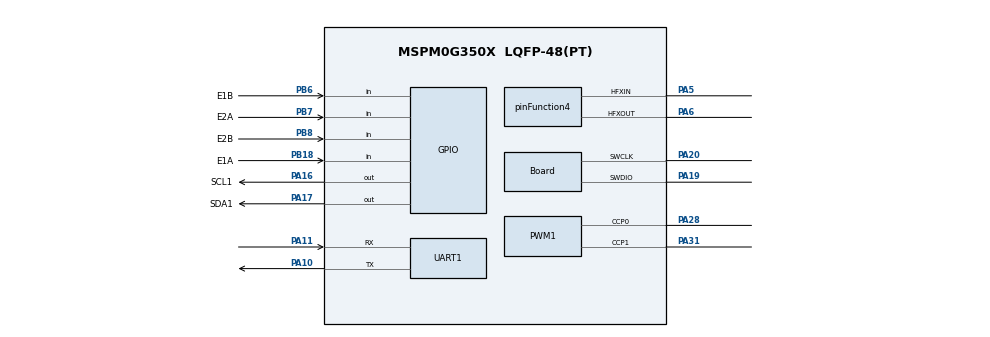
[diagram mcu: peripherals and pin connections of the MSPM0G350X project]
/**
 * @cliArgs --device "MSPM0G350X" --part "Default" --package "LQFP-48(PT)" --product "mspm0_sdk@2.03.00.07"
 * @versions {"tool":"1.22.0+3893"}
 */

/**
 * Import the modules used in this configuration.
 */
const GPIO          = scripting.addModule("/ti/driverlib/GPIO", {}, false);
const GPIO1         = GPIO.addInstance();
const GPIO2         = GPIO.addInstance();
const GPIO3         = GPIO.addInstance();
const GPIO4         = GPIO.addInstance();
const GPIO5         = GPIO.addInstance();
const GPIO6         = GPIO.addInstance();
const GPIO7         = GPIO.addInstance();
const PWM           = scripting.addModule("/ti/driverlib/PWM", {}, false);
const PWM1          = PWM.addInstance();
const SYSCTL        = scripting.addModule("/ti/driverlib/SYSCTL");
const SYSTICK       = scripting.addModule("/ti/driverlib/SYSTICK");
const TIMER         = scripting.addModule("/ti/driverlib/TIMER", {}, false);
const TIMER1        = TIMER.addInstance();
const UART          = scripting.addModule("/ti/driverlib/UART", {}, false);
const UART1         = UART.addInstance();
const ProjectConfig = scripting.addModule("/ti/project_config/ProjectConfig");

/**
 * Write custom configuration values to the imported modules.
 */
const divider6       = system.clockTree["PLL_CLK2X_DIV"];
divider6.divideValue = 4;

const divider7       = system.clockTree["PLL_PDIV"];
divider7.divideValue = 2;

const divider9       = system.clockTree["UDIV"];
divider9.divideValue = 2;

const gate7  = system.clockTree["MFCLKGATE"];
gate7.enable = true;

const gate8  = system.clockTree["MFPCLKGATE"];
gate8.enable = true;

const multiplier2         = system.clockTree["PLL_QDIV"];
multiplier2.multiplyValue = 10;

const mux4       = system.clockTree["EXHFMUX"];
mux4.inputSelect = "EXHFMUX_XTAL";

const mux8       = system.clockTree["HSCLKMUX"];
mux8.inputSelect = "HSCLKMUX_SYSPLL2X";

const mux10       = system.clockTree["MFPCLKMUX"];
mux10.inputSelect = "MFPCLKMUX_HFCLK";

const pinFunction4                        = system.clockTree["HFXT"];
pinFunction4.inputFreq                    = 4;
pinFunction4.enable                       = true;
pinFunction4.peripheral.$assign           = "SYSCTL";
pinFunction4.peripheral.hfxInPin.$assign  = "PA5";
pinFunction4.peripheral.hfxOutPin.$assign = "PA6";

GPIO1.$name                          = "MOTOR";
GPIO1.associatedPins.create(4);
GPIO1.associatedPins[0].assignedPort = "PORTA";
GPIO1.associatedPins[0].$name        = "AIN1_A02";
GPIO1.associatedPins[0].assignedPin  = "12";
GPIO1.associatedPins[1].$name        = "AIN2_B24";
GPIO1.associatedPins[1].assignedPort = "PORTB";
GPIO1.associatedPins[1].assignedPin  = "24";
GPIO1.associatedPins[2].$name        = "BIN1_B20";
GPIO1.associatedPins[2].assignedPort = "PORTB";
GPIO1.associatedPins[2].assignedPin  = "20";
GPIO1.associatedPins[3].$name        = "BIN2_B19";
GPIO1.associatedPins[3].assignedPort = "PORTB";
GPIO1.associatedPins[3].assignedPin  = "19";

const Board                       = scripting.addModule("/ti/driverlib/Board", {}, false);
Board.peripheral.$assign          = "DEBUGSS";
Board.peripheral.swclkPin.$assign = "PA20";
Board.peripheral.swdioPin.$assign = "PA19";

GPIO2.$name                          = "TRACK";
GPIO2.associatedPins.create(7);
GPIO2.associatedPins[0].$name        = "S1";
GPIO2.associatedPins[0].direction    = "INPUT";
GPIO2.associatedPins[0].assignedPort = "PORTA";
GPIO2.associatedPins[0].assignedPin  = "25";
GPIO2.associatedPins[1].$name        = "S2";
GPIO2.associatedPins[1].direction    = "INPUT";
GPIO2.associatedPins[1].assignedPort = "PORTA";
GPIO2.associatedPins[1].assignedPin  = "24";
GPIO2.associatedPins[2].$name        = "S3";
GPIO2.associatedPins[2].direction    = "INPUT";
GPIO2.associatedPins[2].assignedPort = "PORTA";
GPIO2.associatedPins[2].assignedPin  = "23";
GPIO2.associatedPins[3].$name        = "S4";
GPIO2.associatedPins[3].assignedPort = "PORTA";
GPIO2.associatedPins[3].assignedPin  = "21";
GPIO2.associatedPins[3].direction    = "INPUT";
GPIO2.associatedPins[4].$name        = "S5";
GPIO2.associatedPins[4].direction    = "INPUT";
GPIO2.associatedPins[4].assignedPort = "PORTB";
GPIO2.associatedPins[4].assignedPin  = "9";
GPIO2.associatedPins[5].$name        = "S6";
GPIO2.associatedPins[5].direction    = "INPUT";
GPIO2.associatedPins[5].assignedPort = "PORTA";
GPIO2.associatedPins[5].assignedPin  = "13";
GPIO2.associatedPins[6].$name        = "S7";
GPIO2.associatedPins[6].direction    = "INPUT";
GPIO2.associatedPins[6].assignedPort = "PORTA";
GPIO2.associatedPins[6].assignedPin  = "14";

GPIO3.$name                               = "ENCODER";
GPIO3.associatedPins.create(4);
GPIO3.associatedPins[0].$name             = "E1A";
GPIO3.associatedPins[0].direction         = "INPUT";
GPIO3.associatedPins[0].assignedPort      = "PORTB";
GPIO3.associatedPins[0].assignedPin       = "18";
GPIO3.associatedPins[0].interruptEn       = true;
GPIO3.associatedPins[0].interruptPriority = "0";
GPIO3.associatedPins[0].polarity          = "RISE";
GPIO3.associatedPins[0].pin.$assign       = "PB18";
GPIO3.associatedPins[1].$name             = "E1B";
GPIO3.associatedPins[1].direction         = "INPUT";
GPIO3.associatedPins[1].assignedPort      = "PORTB";
GPIO3.associatedPins[1].assignedPin       = "6";
GPIO3.associatedPins[1].interruptEn       = true;
GPIO3.associatedPins[1].interruptPriority = "0";
GPIO3.associatedPins[1].polarity          = "RISE";
GPIO3.associatedPins[1].pin.$assign       = "PB6";
GPIO3.associatedPins[2].$name             = "E2A";
GPIO3.associatedPins[2].assignedPort      = "PORTB";
GPIO3.associatedPins[2].assignedPin       = "7";
GPIO3.associatedPins[2].direction         = "INPUT";
GPIO3.associatedPins[2].interruptEn       = true;
GPIO3.associatedPins[2].interruptPriority = "0";
GPIO3.associatedPins[2].polarity          = "RISE";
GPIO3.associatedPins[2].pin.$assign       = "PB7";
GPIO3.associatedPins[3].$name             = "E2B";
GPIO3.associatedPins[3].assignedPort      = "PORTB";
GPIO3.associatedPins[3].assignedPin       = "8";
GPIO3.associatedPins[3].direction         = "INPUT";
GPIO3.associatedPins[3].interruptEn       = true;
GPIO3.associatedPins[3].interruptPriority = "0";
GPIO3.associatedPins[3].polarity          = "RISE";
GPIO3.associatedPins[3].pin.$assign       = "PB8";

GPIO4.$name                          = "BEEP";
GPIO4.associatedPins[0].$name        = "PIN_12";
GPIO4.associatedPins[0].assignedPort = "PORTA";
GPIO4.associatedPins[0].initialValue = "SET";
GPIO4.associatedPins[0].assignedPin  = "2";

GPIO5.$name                          = "GYRO";
GPIO5.associatedPins.create(2);
GPIO5.associatedPins[0].$name        = "SCL";
GPIO5.associatedPins[0].initialValue = "SET";
GPIO5.associatedPins[0].ioStructure  = "OD";
GPIO5.associatedPins[0].assignedPort = "PORTA";
GPIO5.associatedPins[0].assignedPin  = "0";
GPIO5.associatedPins[1].$name        = "SDA";
GPIO5.associatedPins[1].initialValue = "SET";
GPIO5.associatedPins[1].ioStructure  = "OD";
GPIO5.associatedPins[1].assignedPort = "PORTA";
GPIO5.associatedPins[1].assignedPin  = "1";

GPIO6.$name                          = "KEY";
GPIO6.associatedPins.create(2);
GPIO6.associatedPins[0].$name        = "key1";
GPIO6.associatedPins[0].direction    = "INPUT";
GPIO6.associatedPins[0].assignedPort = "PORTA";
GPIO6.associatedPins[0].assignedPin  = "9";
GPIO6.associatedPins[1].$name        = "key2";
GPIO6.associatedPins[1].direction    = "INPUT";
GPIO6.associatedPins[1].assignedPin  = "8";
GPIO6.associatedPins[1].assignedPort = "PORTA";

GPIO7.$name                          = "OLED";
GPIO7.associatedPins.create(2);
GPIO7.associatedPins[0].$name        = "SCL1";
GPIO7.associatedPins[0].initialValue = "SET";
GPIO7.associatedPins[0].assignedPort = "PORTA";
GPIO7.associatedPins[0].assignedPin  = "16";
GPIO7.associatedPins[0].pin.$assign  = "PA16";
GPIO7.associatedPins[1].$name        = "SDA1";
GPIO7.associatedPins[1].initialValue = "SET";
GPIO7.associatedPins[1].assignedPort = "PORTA";
GPIO7.associatedPins[1].assignedPin  = "17";
GPIO7.associatedPins[1].pin.$assign  = "PA17";

PWM1.$name                              = "PWM_MOTOR";
PWM1.timerStartTimer                    = true;
PWM1.timerCount                         = 10000;
PWM1.peripheral.$assign                 = "TIMG7";
PWM1.peripheral.ccp0Pin.$assign         = "PA28";
PWM1.peripheral.ccp1Pin.$assign         = "PA31";
PWM1.PWM_CHANNEL_0.$name                = "ti_driverlib_pwm_PWMTimerCC0";
PWM1.PWM_CHANNEL_0.invert               = true;
PWM1.PWM_CHANNEL_1.$name                = "ti_driverlib_pwm_PWMTimerCC1";
PWM1.PWM_CHANNEL_1.invert               = true;
PWM1.ccp0PinConfig.direction            = scripting.forceWrite("OUTPUT");
PWM1.ccp0PinConfig.hideOutputInversion  = scripting.forceWrite(false);
PWM1.ccp0PinConfig.onlyInternalResistor = scripting.forceWrite(false);
PWM1.ccp0PinConfig.passedPeripheralType = scripting.forceWrite("Digital");
PWM1.ccp0PinConfig.$name                = "ti_driverlib_gpio_GPIOPinGeneric2";
PWM1.ccp1PinConfig.direction            = scripting.forceWrite("OUTPUT");
PWM1.ccp1PinConfig.hideOutputInversion  = scripting.forceWrite(false);
PWM1.ccp1PinConfig.onlyInternalResistor = scripting.forceWrite(false);
PWM1.ccp1PinConfig.passedPeripheralType = scripting.forceWrite("Digital");
PWM1.ccp1PinConfig.$name                = "ti_driverlib_gpio_GPIOPinGeneric3";

SYSCTL.clockTreeEn           = true;
SYSCTL.forceDefaultClkConfig = true;

SYSTICK.periodEnable  = true;
SYSTICK.systickEnable = true;
SYSTICK.period        = 80;

TIMER1.$name             = "TIMER_0";
TIMER1.timerMode         = "PERIODIC";
TIMER1.timerStartTimer   = true;
TIMER1.interrupts        = ["ZERO"];
TIMER1.timerClkSrc       = "MFCLK";
TIMER1.timerClkPrescale  = 200;
TIMER1.interruptPriority = "3";
TIMER1.timerPeriod       = "5ms";

UART1.uartClkSrc                       = "MFCLK";
UART1.enabledInterrupts                = ["RX"];
UART1.$name                            = "UART_0_DEBUG";
UART1.targetBaudRate                   = 115200;
UART1.peripheral.$assign               = "UART0";
UART1.peripheral.rxPin.$assign         = "PA11";
UART1.peripheral.txPin.$assign         = "PA10";
UART1.txPinConfig.direction            = scripting.forceWrite("OUTPUT");
UART1.txPinConfig.hideOutputInversion  = scripting.forceWrite(false);
UART1.txPinConfig.onlyInternalResistor = scripting.forceWrite(false);
UART1.txPinConfig.passedPeripheralType = scripting.forceWrite("Digital");
UART1.txPinConfig.$name                = "ti_driverlib_gpio_GPIOPinGeneric0";
UART1.rxPinConfig.hideOutputInversion  = scripting.forceWrite(false);
UART1.rxPinConfig.onlyInternalResistor = scripting.forceWrite(false);
UART1.rxPinConfig.passedPeripheralType = scripting.forceWrite("Digital");
UART1.rxPinConfig.$name                = "ti_driverlib_gpio_GPIOPinGeneric1";

ProjectConfig.migrationCondition = true;

/**
 * Pinmux solution for unlocked pins/peripherals. This ensures that minor changes to the automatic solver in a future
 * version of the tool will not impact the pinmux you originally saw.  These lines can be completely deleted in order to
 * re-solve from scratch.
 */
GPIO1.associatedPins[0].pin.$suggestSolution = "PA12";
GPIO1.associatedPins[1].pin.$suggestSolution = "PB24";
GPIO1.associatedPins[2].pin.$suggestSolution = "PB20";
GPIO1.associatedPins[3].pin.$suggestSolution = "PB19";
GPIO2.associatedPins[0].pin.$suggestSolution = "PA25";
GPIO2.associatedPins[1].pin.$suggestSolution = "PA24";
GPIO2.associatedPins[2].pin.$suggestSolution = "PA23";
GPIO2.associatedPins[3].pin.$suggestSolution = "PA21";
GPIO2.associatedPins[4].pin.$suggestSolution = "PB9";
GPIO2.associatedPins[5].pin.$suggestSolution = "PA13";
GPIO2.associatedPins[6].pin.$suggestSolution = "PA14";
GPIO4.associatedPins[0].pin.$suggestSolution = "PA2";
GPIO5.associatedPins[0].pin.$suggestSolution = "PA0";
GPIO5.associatedPins[1].pin.$suggestSolution = "PA1";
GPIO6.associatedPins[0].pin.$suggestSolution = "PA9";
GPIO6.associatedPins[1].pin.$suggestSolution = "PA8";
TIMER1.peripheral.$suggestSolution           = "TIMA0";
